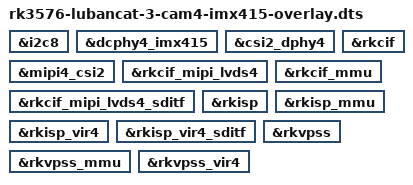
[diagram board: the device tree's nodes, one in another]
/dts-v1/;
/plugin/;

#include <dt-bindings/usb/pd.h>
#include <dt-bindings/gpio/gpio.h>
#include <dt-bindings/pwm/pwm.h>
#include <dt-bindings/pinctrl/rockchip.h>
#include <dt-bindings/input/rk-input.h>
#include <dt-bindings/display/drm_mipi_dsi.h>
#include <dt-bindings/display/rockchip_vop.h>
#include <dt-bindings/sensor-dev.h>

/ {
    fragment@0 {
        target = <&i2c8>;
        __overlay__ {
            status = "okay";
        };
    };

    fragment@1 {
        target = <&dcphy4_imx415>;
        __overlay__ {
            status = "okay";
        };
    };

    fragment@2 {
        target = <&csi2_dphy4>;

        __overlay__ {
            status = "okay";
        };
    };

    fragment@3 {
        target = <&mipi4_csi2>;

        __overlay__ {
            status = "okay";
        };
    };

    fragment@4 {
        target = <&rkcif>;

        __overlay__ {
            status = "okay";
        };
    };

    fragment@5 {
        target = <&rkcif_mipi_lvds4>;

        __overlay__ {
            status = "okay";
        };
    };

    fragment@6 {
        target = <&rkcif_mipi_lvds4_sditf>;

        __overlay__ {
            status = "okay";
        };
    };

    fragment@7 {
        target = <&rkcif_mmu>;

        __overlay__ {
            status = "okay";
        };
    };

    fragment@8 {
        target = <&rkisp>;

        __overlay__ {
            status = "okay";
        };
    };

    fragment@9 {
        target = <&rkisp_mmu>;

        __overlay__ {
            status = "okay";
        };
    };

    fragment@10 {
        target = <&rkisp_vir4>;

        __overlay__ {
            status = "okay";
        };
    };

    fragment@11 {
        target = <&rkisp_vir4_sditf>;

        __overlay__ {
            status = "okay";
        };
    };

    fragment@12 {
        target = <&rkvpss>;

        __overlay__ {
            status = "okay";
        };
    };

    fragment@13 {
        target = <&rkvpss_mmu>;

        __overlay__ {
            status = "okay";
        };
    };

    fragment@14 {
        target = <&rkvpss_vir4>;

        __overlay__ {
            status = "okay";
        };
    };
};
